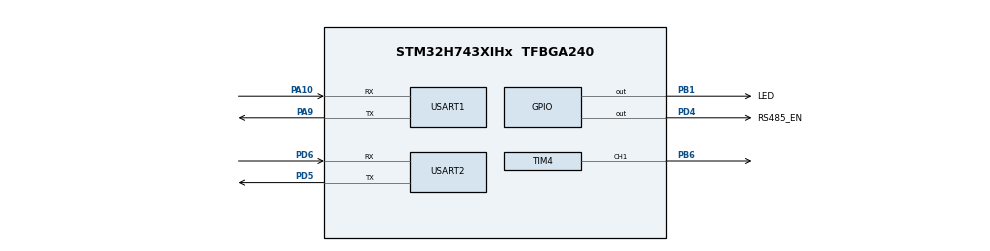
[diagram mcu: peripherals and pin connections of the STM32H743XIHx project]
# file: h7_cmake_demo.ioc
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CORTEX_M7.default_mode_Activation=1
Mcu.Family=STM32H7
Mcu.Name=STM32H743XIHx
Mcu.Package=TFBGA240
NVIC.PriorityGroup=NVIC_PRIORITYGROUP_4
NVIC.TIM4_IRQn=true\:2\:0\:true\:false\:false\:true\:true\:true
NVIC.USART1_IRQn=true\:0\:0\:false\:false\:true\:true\:true\:true
NVIC.USART2_IRQn=true\:0\:0\:false\:false\:true\:true\:true\:true
PA10.Mode=Asynchronous
PA10.Signal=USART1_RX
PA13\ (JTMS/SWDIO).Mode=Serial_Wire
PA13\ (JTMS/SWDIO).Signal=DEBUG_JTMS-SWDIO
PA14\ (JTCK/SWCLK).Mode=Serial_Wire
PA14\ (JTCK/SWCLK).Signal=DEBUG_JTCK-SWCLK
PA9.Mode=Asynchronous
PA9.Signal=USART1_TX
PB1.GPIO_Label=LED
PB1.Signal=GPIO_Output
PB6.Signal=S_TIM4_CH1
PD4.GPIO_Label=RS485_EN
PD4.GPIO_Speed=GPIO_SPEED_FREQ_VERY_HIGH
PD4.Signal=GPIO_Output
PD5.Mode=Asynchronous
PD5.Signal=USART2_TX
PD6.Mode=Asynchronous
PD6.Signal=USART2_RX
PH0-OSC_IN\ (PH0).Mode=HSE-External-Oscillator
PH0-OSC_IN\ (PH0).Signal=RCC_OSC_IN
PH1-OSC_OUT\ (PH1).Mode=HSE-External-Oscillator
PH1-OSC_OUT\ (PH1).Signal=RCC_OSC_OUT
ProjectManager.HeapSize=0x200
ProjectManager.StackSize=0x400
ProjectManager.TargetToolchain=CMake
RCC.ADCFreq_Value=129000000
RCC.APB1Freq_Value=30000000
RCC.APB2Freq_Value=30000000
RCC.APB3Freq_Value=60000000
RCC.APB4Freq_Value=60000000
RCC.CortexFreq_Value=120000000
RCC.D1PPRE=RCC_APB3_DIV2
RCC.D2PPRE1=RCC_APB1_DIV4
RCC.D2PPRE2=RCC_APB2_DIV4
RCC.D3PPRE=RCC_APB4_DIV2
RCC.DIVM1=4
RCC.DIVN1=15
RCC.HCLKFreq_Value=120000000
RCC.PLL2FRACN=0
RCC.PLL3FRACN=0
RCC.PLLFRACN=0
RCC.SYSCLKFreq_VALUE=120000000
RCC.SYSCLKSource=RCC_SYSCLKSOURCE_PLLCLK
RCC.USBFreq_Value=120000000
SH.S_TIM4_CH1.0=TIM4_CH1,Output Compare1 CH1
TIM4.Channel-Output\ Compare1\ CH1=TIM_CHANNEL_1
TIM4.Prescaler=60-1
USART1.VirtualMode-Asynchronous=VM_ASYNC
USART2.VirtualMode-Asynchronous=VM_ASYNC
VP_MEMORYMAP_VS_MEMORYMAP.Mode=CurAppReg
VP_TIM4_VS_ClockSourceINT.Mode=Internal
board=custom

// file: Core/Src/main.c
/* USER CODE BEGIN Header */
/**
  ******************************************************************************
  * @file           : main.c
  * @brief          : Main program body
  ******************************************************************************
  * @attention
  *
  * Copyright (c) 2025 STMicroelectronics.
  * All rights reserved.
  *
  * This software is licensed under terms that can be found in the LICENSE file
  * in the root directory of this software component.
  * If no LICENSE file comes with this software, it is provided AS-IS.
  *
  ******************************************************************************
  */
/* USER CODE END Header */
#include "main.h"

/* USER CODE BEGIN Includes */

//配置: https://blog.csdn.net/2501_92678806/article/details/155848669
#include "bsp.h"
#include "modbus_slave.h"

/* USER CODE END Includes */

TIM_HandleTypeDef htim4;

UART_HandleTypeDef huart1;
UART_HandleTypeDef huart2;

void SystemClock_Config(void);
static void MPU_Config(void);
static void MX_GPIO_Init(void);
static void MX_TIM4_Init(void);
static void MX_USART2_UART_Init(void);
static void MX_USART1_UART_Init(void);

int main(void)
{

  /* MPU Configuration--------------------------------------------------------*/
  MPU_Config();

  /* MCU Configuration--------------------------------------------------------*/

  /* Reset of all peripherals, Initializes the Flash interface and the Systick. */
  HAL_Init();

  /* Configure the system clock */
  SystemClock_Config();

  /* Initialize all configured peripherals */
  MX_GPIO_Init();
  MX_TIM4_Init();
  MX_USART2_UART_Init();
  MX_USART1_UART_Init();
  /* USER CODE BEGIN 2 */
  bsp_Init();

  int ret = 0;

  /* USER CODE END 2 */

  /* Infinite loop */
  /* USER CODE BEGIN WHILE */
  while (1)
  {
    bsp_Idle();
    // MODS_ReciveNew(0x00);
    // HAL_GPIO_WritePin(LED_GPIO_Port, LED_Pin, GPIO_PIN_RESET);
    // HAL_GPIO_WritePin(LED_GPIO_Port, LED_Pin, GPIO_PIN_SET);
    // HAL_Delay(1000);
    /* USER CODE END WHILE */

  }
}

void SystemClock_Config(void)
{
  RCC_OscInitTypeDef RCC_OscInitStruct = {0};
  RCC_ClkInitTypeDef RCC_ClkInitStruct = {0};

  /** Supply configuration update enable
  */
  HAL_PWREx_ConfigSupply(PWR_LDO_SUPPLY);

  /** Configure the main internal regulator output voltage
  */
  __HAL_PWR_VOLTAGESCALING_CONFIG(PWR_REGULATOR_VOLTAGE_SCALE3);

  while(!__HAL_PWR_GET_FLAG(PWR_FLAG_VOSRDY)) {}

  /** Initializes the RCC Oscillators according to the specified parameters
  * in the RCC_OscInitTypeDef structure.
  */
  RCC_OscInitStruct.OscillatorType = RCC_OSCILLATORTYPE_HSI;
  RCC_OscInitStruct.HSIState = RCC_HSI_DIV1;
  RCC_OscInitStruct.HSICalibrationValue = RCC_HSICALIBRATION_DEFAULT;
  RCC_OscInitStruct.PLL.PLLState = RCC_PLL_ON;
  RCC_OscInitStruct.PLL.PLLSource = RCC_PLLSOURCE_HSI;
  RCC_OscInitStruct.PLL.PLLM = 4;
  RCC_OscInitStruct.PLL.PLLN = 15;
  RCC_OscInitStruct.PLL.PLLP = 2;
  RCC_OscInitStruct.PLL.PLLQ = 2;
  RCC_OscInitStruct.PLL.PLLR = 2;
  RCC_OscInitStruct.PLL.PLLRGE = RCC_PLL1VCIRANGE_3;
  RCC_OscInitStruct.PLL.PLLVCOSEL = RCC_PLL1VCOWIDE;
  RCC_OscInitStruct.PLL.PLLFRACN = 0;
  if (HAL_RCC_OscConfig(&RCC_OscInitStruct) != HAL_OK)
  {
    Error_Handler();
  }

  /** Initializes the CPU, AHB and APB buses clocks
  */
  RCC_ClkInitStruct.ClockType = RCC_CLOCKTYPE_HCLK|RCC_CLOCKTYPE_SYSCLK
                              |RCC_CLOCKTYPE_PCLK1|RCC_CLOCKTYPE_PCLK2
                              |RCC_CLOCKTYPE_D3PCLK1|RCC_CLOCKTYPE_D1PCLK1;
  RCC_ClkInitStruct.SYSCLKSource = RCC_SYSCLKSOURCE_PLLCLK;
  RCC_ClkInitStruct.SYSCLKDivider = RCC_SYSCLK_DIV1;
  RCC_ClkInitStruct.AHBCLKDivider = RCC_HCLK_DIV1;
  RCC_ClkInitStruct.APB3CLKDivider = RCC_APB3_DIV2;
  RCC_ClkInitStruct.APB1CLKDivider = RCC_APB1_DIV4;
  RCC_ClkInitStruct.APB2CLKDivider = RCC_APB2_DIV4;
  RCC_ClkInitStruct.APB4CLKDivider = RCC_APB4_DIV2;

  if (HAL_RCC_ClockConfig(&RCC_ClkInitStruct, FLASH_LATENCY_2) != HAL_OK)
  {
    Error_Handler();
  }
}

static void MX_TIM4_Init(void)
{

  TIM_ClockConfigTypeDef sClockSourceConfig = {0};
  TIM_MasterConfigTypeDef sMasterConfig = {0};
  TIM_OC_InitTypeDef sConfigOC = {0};

  htim4.Instance = TIM4;
  htim4.Init.Prescaler = 60-1;
  htim4.Init.CounterMode = TIM_COUNTERMODE_UP;
  htim4.Init.Period = 65535;
  htim4.Init.ClockDivision = TIM_CLOCKDIVISION_DIV1;
  htim4.Init.AutoReloadPreload = TIM_AUTORELOAD_PRELOAD_DISABLE;
  if (HAL_TIM_Base_Init(&htim4) != HAL_OK)
  {
    Error_Handler();
  }
  sClockSourceConfig.ClockSource = TIM_CLOCKSOURCE_INTERNAL;
  if (HAL_TIM_ConfigClockSource(&htim4, &sClockSourceConfig) != HAL_OK)
  {
    Error_Handler();
  }
  if (HAL_TIM_OC_Init(&htim4) != HAL_OK)
  {
    Error_Handler();
  }
  sMasterConfig.MasterOutputTrigger = TIM_TRGO_RESET;
  sMasterConfig.MasterSlaveMode = TIM_MASTERSLAVEMODE_DISABLE;
  if (HAL_TIMEx_MasterConfigSynchronization(&htim4, &sMasterConfig) != HAL_OK)
  {
    Error_Handler();
  }
  sConfigOC.OCMode = TIM_OCMODE_TIMING;
  sConfigOC.Pulse = 0;
  sConfigOC.OCPolarity = TIM_OCPOLARITY_HIGH;
  sConfigOC.OCFastMode = TIM_OCFAST_DISABLE;
  if (HAL_TIM_OC_ConfigChannel(&htim4, &sConfigOC, TIM_CHANNEL_1) != HAL_OK)
  {
    Error_Handler();
  }
  HAL_TIM_MspPostInit(&htim4);

}

static void MX_USART1_UART_Init(void)
{

  huart1.Instance = USART1;
  huart1.Init.BaudRate = 115200;
  huart1.Init.WordLength = UART_WORDLENGTH_8B;
  huart1.Init.StopBits = UART_STOPBITS_1;
  huart1.Init.Parity = UART_PARITY_NONE;
  huart1.Init.Mode = UART_MODE_TX_RX;
  huart1.Init.HwFlowCtl = UART_HWCONTROL_NONE;
  huart1.Init.OverSampling = UART_OVERSAMPLING_16;
  huart1.Init.OneBitSampling = UART_ONE_BIT_SAMPLE_DISABLE;
  huart1.Init.ClockPrescaler = UART_PRESCALER_DIV1;
  huart1.AdvancedInit.AdvFeatureInit = UART_ADVFEATURE_NO_INIT;
  if (HAL_UART_Init(&huart1) != HAL_OK)
  {
    Error_Handler();
  }
  if (HAL_UARTEx_SetTxFifoThreshold(&huart1, UART_TXFIFO_THRESHOLD_1_8) != HAL_OK)
  {
    Error_Handler();
  }
  if (HAL_UARTEx_SetRxFifoThreshold(&huart1, UART_RXFIFO_THRESHOLD_1_8) != HAL_OK)
  {
    Error_Handler();
  }
  if (HAL_UARTEx_DisableFifoMode(&huart1) != HAL_OK)
  {
    Error_Handler();
  }

}

static void MX_USART2_UART_Init(void)
{

  huart2.Instance = USART2;
  huart2.Init.BaudRate = 115200;
  huart2.Init.WordLength = UART_WORDLENGTH_8B;
  huart2.Init.StopBits = UART_STOPBITS_1;
  huart2.Init.Parity = UART_PARITY_NONE;
  huart2.Init.Mode = UART_MODE_TX_RX;
  huart2.Init.HwFlowCtl = UART_HWCONTROL_NONE;
  huart2.Init.OverSampling = UART_OVERSAMPLING_16;
  huart2.Init.OneBitSampling = UART_ONE_BIT_SAMPLE_DISABLE;
  huart2.Init.ClockPrescaler = UART_PRESCALER_DIV1;
  huart2.AdvancedInit.AdvFeatureInit = UART_ADVFEATURE_NO_INIT;
  if (HAL_UART_Init(&huart2) != HAL_OK)
  {
    Error_Handler();
  }
  if (HAL_UARTEx_SetTxFifoThreshold(&huart2, UART_TXFIFO_THRESHOLD_1_8) != HAL_OK)
  {
    Error_Handler();
  }
  if (HAL_UARTEx_SetRxFifoThreshold(&huart2, UART_RXFIFO_THRESHOLD_1_8) != HAL_OK)
  {
    Error_Handler();
  }
  if (HAL_UARTEx_DisableFifoMode(&huart2) != HAL_OK)
  {
    Error_Handler();
  }

}

static void MX_GPIO_Init(void)
{
  GPIO_InitTypeDef GPIO_InitStruct = {0};

  /* GPIO Ports Clock Enable */
  __HAL_RCC_GPIOD_CLK_ENABLE();
  __HAL_RCC_GPIOB_CLK_ENABLE();
  __HAL_RCC_GPIOA_CLK_ENABLE();
  __HAL_RCC_GPIOH_CLK_ENABLE();

  /*Configure GPIO pin Output Level */
  HAL_GPIO_WritePin(RS485_EN_GPIO_Port, RS485_EN_Pin, GPIO_PIN_RESET);

  /*Configure GPIO pin Output Level */
  HAL_GPIO_WritePin(LED_GPIO_Port, LED_Pin, GPIO_PIN_RESET);

  /*Configure GPIO pin : RS485_EN_Pin */
  GPIO_InitStruct.Pin = RS485_EN_Pin;
  GPIO_InitStruct.Mode = GPIO_MODE_OUTPUT_PP;
  GPIO_InitStruct.Pull = GPIO_NOPULL;
  GPIO_InitStruct.Speed = GPIO_SPEED_FREQ_VERY_HIGH;
  HAL_GPIO_Init(RS485_EN_GPIO_Port, &GPIO_InitStruct);

  /*Configure GPIO pin : LED_Pin */
  GPIO_InitStruct.Pin = LED_Pin;
  GPIO_InitStruct.Mode = GPIO_MODE_OUTPUT_PP;
  GPIO_InitStruct.Pull = GPIO_NOPULL;
  GPIO_InitStruct.Speed = GPIO_SPEED_FREQ_LOW;
  HAL_GPIO_Init(LED_GPIO_Port, &GPIO_InitStruct);

}

 /* MPU Configuration */

void MPU_Config(void)
{
  MPU_Region_InitTypeDef MPU_InitStruct = {0};

  /* Disables the MPU */
  HAL_MPU_Disable();

  /** Initializes and configures the Region and the memory to be protected
  */
  MPU_InitStruct.Enable = MPU_REGION_ENABLE;
  MPU_InitStruct.Number = MPU_REGION_NUMBER0;
  MPU_InitStruct.BaseAddress = 0x0;
  MPU_InitStruct.Size = MPU_REGION_SIZE_4GB;
  MPU_InitStruct.SubRegionDisable = 0x87;
  MPU_InitStruct.TypeExtField = MPU_TEX_LEVEL0;
  MPU_InitStruct.AccessPermission = MPU_REGION_NO_ACCESS;
  MPU_InitStruct.DisableExec = MPU_INSTRUCTION_ACCESS_DISABLE;
  MPU_InitStruct.IsShareable = MPU_ACCESS_SHAREABLE;
  MPU_InitStruct.IsCacheable = MPU_ACCESS_NOT_CACHEABLE;
  MPU_InitStruct.IsBufferable = MPU_ACCESS_NOT_BUFFERABLE;

  HAL_MPU_ConfigRegion(&MPU_InitStruct);
  /* Enables the MPU */
  HAL_MPU_Enable(MPU_PRIVILEGED_DEFAULT);

}

void Error_Handler(void)
{
  __disable_irq();
  while (1)
  {
  }
}
